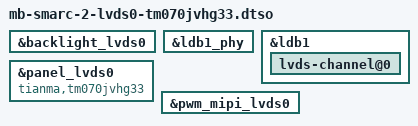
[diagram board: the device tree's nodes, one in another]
// SPDX-License-Identifier: (GPL-2.0-or-later OR MIT)
/*
 * Copyright (c) 2018-2024 TQ-Systems GmbH <linux@ew.tq-group.com>,
 * D-82229 Seefeld, Germany.
 * Author: Alexander Stein
 */

/dts-v1/;
/plugin/;

&backlight_lvds0 {
	status = "okay";
};

&ldb1_phy {
	status = "okay";
};

&ldb1 {
	status = "okay";

	lvds-channel@0 {
		status = "okay";
	};
};

&panel_lvds0 {
	compatible = "tianma,tm070jvhg33";
	status = "okay";
};

&pwm_mipi_lvds0 {
	status = "okay";
};
